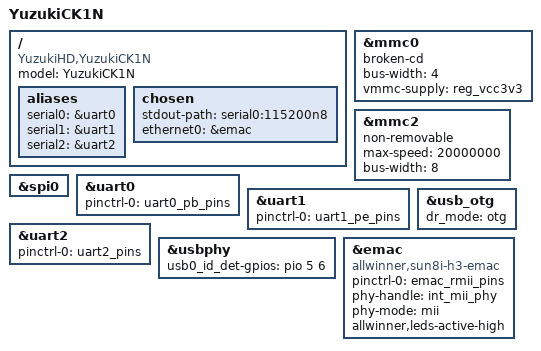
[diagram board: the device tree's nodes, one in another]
/dts-v1/;
#include "sun8i-v3x-uboot.dtsi"
#include "sunxi-common-regulators.dtsi"

/ {
	model = "YuzukiCK1N";
	compatible = "YuzukiHD,YuzukiCK1N", "allwinner,sun8i-v3x";

	aliases {
		serial0 = &uart0;
		serial1 = &uart1;
		serial2 = &uart2;
	};

	chosen {
		stdout-path = "serial0:115200n8";
		ethernet0 = &emac;
	};
};

&mmc0 {
	broken-cd;
	bus-width = <4>;
	vmmc-supply = <&reg_vcc3v3>;
	status = "okay";
};

&mmc2 {
    non-removable;
    max-speed = <20000000>;
    bus-width = <8>;
    status = "okay";
};

&spi0 {
    status = "okay";
};

&uart0 {
	pinctrl-0 = <&uart0_pb_pins>;
	pinctrl-names = "default";
	status = "okay";
};

&uart1 {
	pinctrl-0 = <&uart1_pe_pins>;
	pinctrl-names = "default";
	status = "okay";
};

&uart2 {
	pinctrl-0 = <&uart2_pins>;
	pinctrl-names = "default";
	status = "okay";
};

&usb_otg {
	dr_mode = "otg";
	status = "okay";
};

&usbphy {
	usb0_id_det-gpios = <&pio 5 6 GPIO_ACTIVE_HIGH>;
	status = "okay";
};

&emac {
    compatible = "allwinner,sun8i-h3-emac";
    pinctrl-0 = <&emac_rmii_pins>;
    phy-handle = <&int_mii_phy>;
    phy-mode = "mii";
    allwinner,leds-active-high;
    status = "okay";
};
